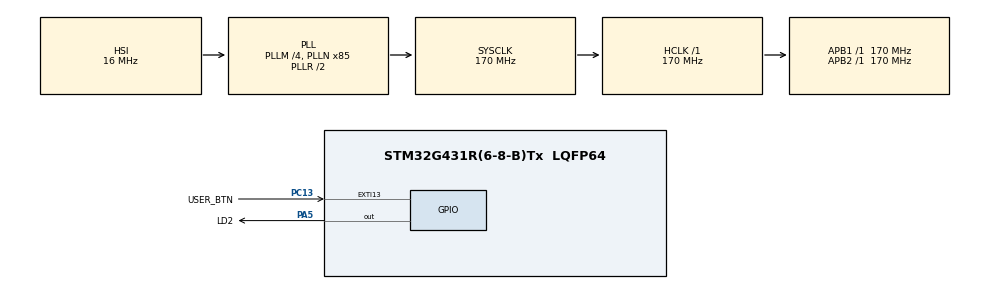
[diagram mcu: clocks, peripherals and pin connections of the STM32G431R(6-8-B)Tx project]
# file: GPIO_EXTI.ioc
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Mcu.Family=STM32G4
Mcu.Name=STM32G431R(6-8-B)Tx
Mcu.Package=LQFP64
NUCLEO-G431RB.Bsp_Common_DEMO=true
NVIC.EXTI15_10_IRQn=true\:5\:0\:true\:false\:true\:true\:true\:true
NVIC.PriorityGroup=NVIC_PRIORITYGROUP_4
PA13.GPIO_Label=T_SWDIO
PA13.Mode=Serial_Wire
PA13.Signal=SYS_JTMS-SWDIO
PA14.GPIO_Label=T_SWCLK
PA14.Mode=Serial_Wire
PA14.Signal=SYS_JTCK-SWCLK
PA5.GPIO_Label=LD2
PA5.Signal=GPIO_Output
PC13.GPIO_Label=USER_BTN
PC13.Signal=GPXTI13
ProjectManager.HeapSize=0x200
ProjectManager.StackSize=0x400
ProjectManager.TargetToolchain=CMake
RCC.ADC12Freq_Value=170000000
RCC.AHBFreq_Value=170000000
RCC.APB1Freq_Value=170000000
RCC.APB1TimFreq_Value=170000000
RCC.APB2Freq_Value=170000000
RCC.APB2TimFreq_Value=170000000
RCC.CortexFreq_Value=170000000
RCC.EXTERNAL_CLOCK_VALUE=12288000
RCC.HCLKFreq_Value=170000000
RCC.HSE_VALUE=24000000
RCC.HSI48_VALUE=48000000
RCC.HSI_VALUE=16000000
RCC.LSE_VALUE=32768
RCC.PLLM=RCC_PLLM_DIV4
RCC.PLLN=85
RCC.RTCClockSelection=RCC_RTCCLKSOURCE_LSE
RCC.SYSCLKFreq_VALUE=170000000
RCC.SYSCLKSource=RCC_SYSCLKSOURCE_PLLCLK
RCC.USBFreq_Value=170000000
RCC.VCOOutputFreq_Value=340000000
VP_NUCLEO-G431RB_VS_BSP_COMMON.Mode=COMMON
VP_SYS_VS_DBSignals.Mode=DisableDeadBatterySignals
board=NUCLEO-G431RB

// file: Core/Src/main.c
/* USER CODE BEGIN Header */
/**
  ******************************************************************************
  * @file           : main.c
  * @brief          : Main program body
  ******************************************************************************
  */
/* USER CODE END Header */
#include "main.h"

__IO uint32_t BspButtonState = BUTTON_RELEASED;

/* USER CODE BEGIN PV */

/** @brief 按键去抖：记录上次有效触发的 tick，用于防抖判断 */
static uint32_t btn_debounce_tick = 0;

/** @brief 去抖间隔（毫秒），小于此间隔的中断将被忽略 */
#define DEBOUNCE_DELAY_MS  50U

/* USER CODE END PV */

void SystemClock_Config(void);
static void MX_GPIO_Init(void);

int main(void)
{

  /* MCU Configuration--------------------------------------------------------*/

  /* Reset of all peripherals, Initializes the Flash interface and the Systick. */
  HAL_Init();

  /* Configure the system clock */
  SystemClock_Config();

  /* Initialize all configured peripherals */
  MX_GPIO_Init();

  /* Infinite loop */
  while (1)
  {

  }
}

void SystemClock_Config(void)
{
  RCC_OscInitTypeDef RCC_OscInitStruct = {0};
  RCC_ClkInitTypeDef RCC_ClkInitStruct = {0};

  /** Configure the main internal regulator output voltage
  */
  HAL_PWREx_ControlVoltageScaling(PWR_REGULATOR_VOLTAGE_SCALE1_BOOST);

  /** Initializes the RCC Oscillators according to the specified parameters
  * in the RCC_OscInitTypeDef structure.
  */
  RCC_OscInitStruct.OscillatorType = RCC_OSCILLATORTYPE_HSI;
  RCC_OscInitStruct.HSIState = RCC_HSI_ON;
  RCC_OscInitStruct.HSICalibrationValue = RCC_HSICALIBRATION_DEFAULT;
  RCC_OscInitStruct.PLL.PLLState = RCC_PLL_ON;
  RCC_OscInitStruct.PLL.PLLSource = RCC_PLLSOURCE_HSI;
  RCC_OscInitStruct.PLL.PLLM = RCC_PLLM_DIV4;
  RCC_OscInitStruct.PLL.PLLN = 85;
  RCC_OscInitStruct.PLL.PLLP = RCC_PLLP_DIV2;
  RCC_OscInitStruct.PLL.PLLQ = RCC_PLLQ_DIV2;
  RCC_OscInitStruct.PLL.PLLR = RCC_PLLR_DIV2;
  if (HAL_RCC_OscConfig(&RCC_OscInitStruct) != HAL_OK)
  {
    Error_Handler();
  }

  /** Initializes the CPU, AHB and APB buses clocks
  */
  RCC_ClkInitStruct.ClockType = RCC_CLOCKTYPE_HCLK|RCC_CLOCKTYPE_SYSCLK
                              |RCC_CLOCKTYPE_PCLK1|RCC_CLOCKTYPE_PCLK2;
  RCC_ClkInitStruct.SYSCLKSource = RCC_SYSCLKSOURCE_PLLCLK;
  RCC_ClkInitStruct.AHBCLKDivider = RCC_SYSCLK_DIV1;
  RCC_ClkInitStruct.APB1CLKDivider = RCC_HCLK_DIV1;
  RCC_ClkInitStruct.APB2CLKDivider = RCC_HCLK_DIV1;

  if (HAL_RCC_ClockConfig(&RCC_ClkInitStruct, FLASH_LATENCY_4) != HAL_OK)
  {
    Error_Handler();
  }
}

static void MX_GPIO_Init(void)
{
  GPIO_InitTypeDef GPIO_InitStruct = {0};

  /* GPIO Ports Clock Enable */
  __HAL_RCC_GPIOC_CLK_ENABLE();
  __HAL_RCC_GPIOA_CLK_ENABLE();

  /*Configure GPIO pin Output Level */
  HAL_GPIO_WritePin(LD2_GPIO_Port, LD2_Pin, GPIO_PIN_RESET);

  /*Configure GPIO pin : USER_BTN_Pin */
  GPIO_InitStruct.Pin = USER_BTN_Pin;
  GPIO_InitStruct.Mode = GPIO_MODE_IT_RISING;
  GPIO_InitStruct.Pull = GPIO_NOPULL;
  HAL_GPIO_Init(USER_BTN_GPIO_Port, &GPIO_InitStruct);

  /*Configure GPIO pin : LD2_Pin */
  GPIO_InitStruct.Pin = LD2_Pin;
  GPIO_InitStruct.Mode = GPIO_MODE_OUTPUT_PP;
  GPIO_InitStruct.Pull = GPIO_NOPULL;
  GPIO_InitStruct.Speed = GPIO_SPEED_FREQ_LOW;
  HAL_GPIO_Init(LD2_GPIO_Port, &GPIO_InitStruct);

  /* EXTI interrupt init*/
  HAL_NVIC_SetPriority(EXTI15_10_IRQn, 5, 0);
  HAL_NVIC_EnableIRQ(EXTI15_10_IRQn);

}

/* USER CODE BEGIN 4 */

/**
  * @brief  GPIO 外部中断回调函数（重写 HAL 弱回调）
  * @param  GPIO_Pin: 触发中断的引脚号
  * @retval None
  */
void HAL_GPIO_EXTI_Callback(uint16_t GPIO_Pin)
{
  /* 判断是否为用户按键 B1（PC13）触发的中断 */
  if (GPIO_Pin == USER_BTN_Pin)
  {
    uint32_t now = HAL_GetTick();

    /* 去抖动：若距上次有效触发不足 DEBOUNCE_DELAY_MS 毫秒，则忽略本次中断 */
    if ((now - btn_debounce_tick) < DEBOUNCE_DELAY_MS)
    {
      return;
    }

    /* 更新去抖计时，触发有效按键响应 */
    btn_debounce_tick = now;
    HAL_GPIO_TogglePin(LD2_GPIO_Port, LD2_Pin);
  }
}

/* USER CODE END 4 */

void Error_Handler(void)
{
  __disable_irq();
  while (1)
  {
  }
}
